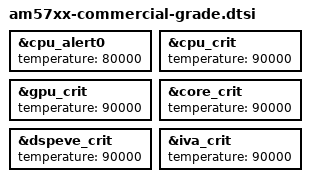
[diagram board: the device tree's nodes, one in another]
&cpu_alert0 {
	temperature = <80000>; /* milliCelsius */
};

&cpu_crit {
	temperature = <90000>; /* milliCelsius */
};

&gpu_crit {
	temperature = <90000>; /* milliCelsius */
};

&core_crit {
	temperature = <90000>; /* milliCelsius */
};

&dspeve_crit {
	temperature = <90000>; /* milliCelsius */
};

&iva_crit {
	temperature = <90000>; /* milliCelsius */
};
